VERSION ""

NS_ :

BS_:

BU_: ACU JETSON

BO_ 3221225472 VECTOR__INDEPENDENT_SIG_MSG: 0 Vector__XXX
 SG_ NewSignal_0023 : 24|8@1+ (1,0) [0|0] "" Vector__XXX
 SG_ NewSignal_0022 : 16|8@1+ (1,0) [0|0] "" Vector__XXX
 SG_ NewSignal_0021 : 8|8@1+ (10,0) [0|0] "" Vector__XXX

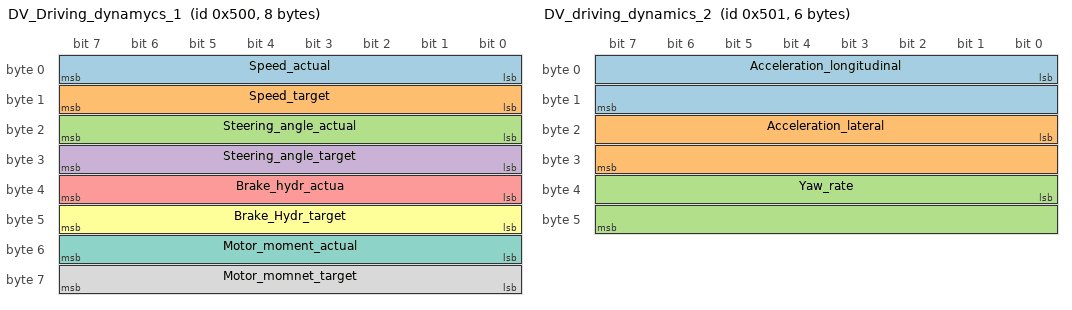
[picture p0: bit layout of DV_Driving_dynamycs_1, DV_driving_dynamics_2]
BO_ 1280 DV_Driving_dynamycs_1: 8 ACU
 SG_ Speed_actual : 0|8@1+ (1,0) [0|0] "Km/h" Vector__XXX
 SG_ Speed_target : 8|8@1+ (1,0) [0|0] "Km/h" Vector__XXX
 SG_ Steering_angle_actual : 16|8@1- (0.5,0) [0|0] "º" Vector__XXX
 SG_ Steering_angle_target : 24|8@1- (0.5,0) [0|0] "º" Vector__XXX
 SG_ Brake_hydr_actua : 32|8@1+ (1,0) [0|0] "%" Vector__XXX
 SG_ Brake_Hydr_target : 40|8@1+ (1,0) [0|0] "%" Vector__XXX
 SG_ Motor_moment_actual : 48|8@1- (1,0) [0|0] "%" Vector__XXX
 SG_ Motor_momnet_target : 56|8@1- (1,0) [0|0] "%" Vector__XXX

BO_ 1281 DV_driving_dynamics_2: 6 JETSON
 SG_ Acceleration_longitudinal : 0|16@1- (0.001953125,0) [0|0] "m/s^2" Vector__XXX
 SG_ Acceleration_lateral : 16|16@1- (0.001953125,0) [0|0] "m/s^2" Vector__XXX
 SG_ Yaw_rate : 32|16@1- (0.0078125,0) [0|0] "º/s" Vector__XXX

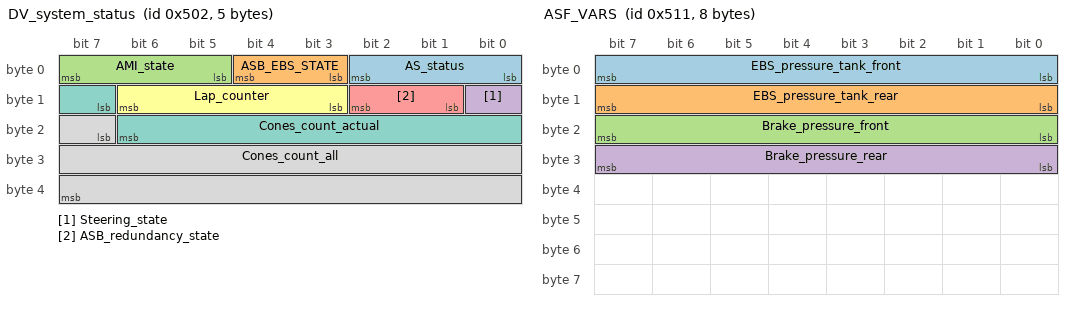
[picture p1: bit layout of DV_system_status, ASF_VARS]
BO_ 1282 DV_system_status: 5 ACU
 SG_ AS_status : 0|3@1+ (1,0) [0|0] "" Vector__XXX
 SG_ ASB_EBS_STATE : 3|2@1+ (1,0) [0|0] "" Vector__XXX
 SG_ AMI_state : 5|3@1+ (1,0) [0|0] "" Vector__XXX
 SG_ Steering_state : 8|1@1+ (1,0) [0|0] "" Vector__XXX
 SG_ ASB_redundancy_state : 9|2@1+ (1,0) [0|0] "" Vector__XXX
 SG_ Lap_counter : 11|4@1+ (1,0) [0|0] "" Vector__XXX
 SG_ Cones_count_actual : 15|8@1+ (1,0) [0|0] "" Vector__XXX
 SG_ Cones_count_all : 23|17@1+ (1,0) [0|0] "" Vector__XXX

BO_ 1297 ASF_VARS: 8 ACU
 SG_ EBS_pressure_tank_front : 0|8@1+ (0.1,0) [0|0] "bar" Vector__XXX
 SG_ EBS_pressure_tank_rear : 8|8@1+ (0.1,0) [0|0] "bar" Vector__XXX
 SG_ Brake_pressure_front : 16|8@1+ (1,0) [0|0] "bar" Vector__XXX
 SG_ Brake_pressure_rear : 24|8@1+ (1,0) [0|0] "bar" Vector__XXX

VAL_ 1282 AS_status 1 "OFF" 2 "READY" 3 "DRIVING" 4 "EMERGENCY" 5 "FINISH" ;
VAL_ 1282 ASB_EBS_STATE 1 "ASB_EBS_state_deactivated" 2 "ASB_EBS_state_initial_checkup_passed" 3 "ASB_EBS_state_activated " ;
VAL_ 1282 AMI_state 1 "AMI_state_acceleration" 2 "AMI_state_skidpad " 3 "AMI_state_trackdrive" 4 "AMI_state_braketest" 5 "AMI_state_inspection " 6 "AMI_state_autocross" ;
VAL_ 1282 ASB_redundancy_state 1 "ASB_redundancy_state_deactivated" 2 "ASB_redundancy_state_engaged " 3 "ASB_redundancy_state_initial_checkup_passed" ;
